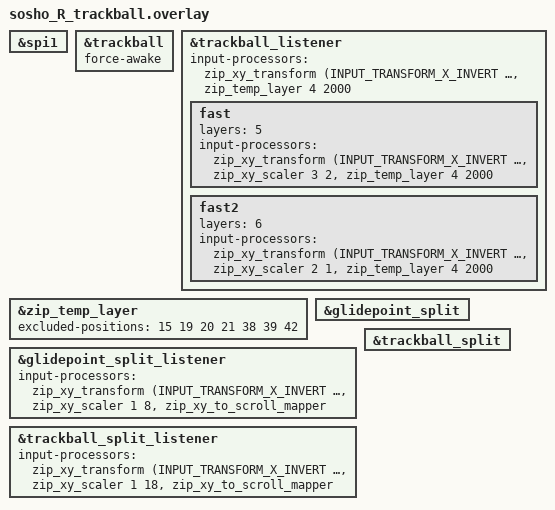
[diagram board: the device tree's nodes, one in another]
#include "sosho_R.dtsi"

/*
glidepoint_listnerは右手のトラックパッド
glidepoint_split_listenerとtrackball_split_listenerは
左手のトラックパッドとトラックボールの受けです。
ここにinput-processorというオプションをつけると、いろんな動きができます。
代表的なものを書いておきます。

・ポインタの移動を早くしたいとき
&zip_xy_scalerを使います。
分子 分母の順に数字を指定します。2 1なら2倍です。
input-processors = <&zip_xy_scaler 2 1>;

・スクロールを割り当てたいとき
zip_xy_to_scroll_mapperを使います。
ポインティングデバイスの動きをスクロールに変換してくれます。
input-processors = <&zip_xy_to_scroll_mapper>;

・移動を反転したいとき
zip_xy_transformを使います。
これは&trackball_listenerで実際に使っています。

これらオプションは複数併記することもできます。
input-processors = <&zip_xy_scaler 1 3>,<&zip_xy_to_scroll_mapper>;

詳しい情報はzmkのドキュメントを確認してください。
https://zmk.dev/docs/keymaps/input-processors
*/

&spi1 { status = "okay"; };
//force-awake: キーボード使用中(ZMK が ACTIVE の間)はセンサーを省電力モードに落とさない
//タイピング後にボールを動かしたとき反応が遅れる/拾わないのを防ぐ。放置して ZMK が IDLE になると通常の省電力に戻る
&trackball {
	status = "okay";
	force-awake;
};
&trackball_listener {
	status = "okay";
	/*
	右手トラックボール(カーソル)
	・速さ: 分子 分母 の順で zip_xy_scaler を足す(2 1 = 2倍)。今は等倍
	・オートマウス: 動かすとレイヤー4(マウス)を2000ms有効にする
	*/
	input-processors = <&zip_xy_transform (INPUT_TRANSFORM_X_INVERT | INPUT_TRANSFORM_Y_INVERT)>,
	                   <&zip_temp_layer 4 2000>;

	//レイヤー5(マウスレイヤーで D を押している間)は 1.5倍
	fast {
		layers = <5>;
		input-processors = <&zip_xy_transform (INPUT_TRANSFORM_X_INVERT | INPUT_TRANSFORM_Y_INVERT)>,
		                   <&zip_xy_scaler 3 2>, <&zip_temp_layer 4 2000>;
	};

	//レイヤー6(マウスレイヤーで位置42を押している間)は 2倍
	fast2 {
		layers = <6>;
		input-processors = <&zip_xy_transform (INPUT_TRANSFORM_X_INVERT | INPUT_TRANSFORM_Y_INVERT)>,
		                   <&zip_xy_scaler 2 1>, <&zip_temp_layer 4 2000>;
	};
};

//オートマウス中にクリックキー(位置19 20 21 38 39)と高速キー(位置15 42)を押してもレイヤーを抜けない
//それ以外のキーを押すとすぐ抜ける
&zip_temp_layer {
	excluded-positions = <15 19 20 21 38 39 42>;
};

&glidepoint_split { status = "okay"; };
&glidepoint_split_listener {
    status = "okay";
	/*
	左手トラックパッドをスクロールにする設定
	・速さ: zip_xy_scaler の2つ目の数字を大きくすると遅くなる
	・向き: zip_xy_transform で縦横とも反転している。縦だけ反転なら INPUT_TRANSFORM_Y_INVERT だけにする
	*/
	input-processors = <&zip_xy_transform (INPUT_TRANSFORM_X_INVERT | INPUT_TRANSFORM_Y_INVERT)>,
	                   <&zip_xy_scaler 1 8>, <&zip_xy_to_scroll_mapper>;
};

&trackball_split { status = "okay"; };
&trackball_split_listener {
	status = "okay";
	//左手トラックボールに戻したとき用(以前の設定と同じ)
	input-processors = <&zip_xy_transform (INPUT_TRANSFORM_X_INVERT | INPUT_TRANSFORM_Y_INVERT)>,
	                   <&zip_xy_scaler 1 18>, <&zip_xy_to_scroll_mapper>;
};
